# STM32G474 register map
File version: 2.9
CPU: CM4 r0p1, little endian, MPU, FPU, 4 interrupt priority bits
Registers are 32-bit, read-write, reset 0x0 unless marked. A register's access mark holds for its fields unless they carry their own. Offsets are from the block's base; [hi:lo] are bit positions; {n}, {i} and the like mark numbered series.

## PWR — Power control
Base 0x40007000
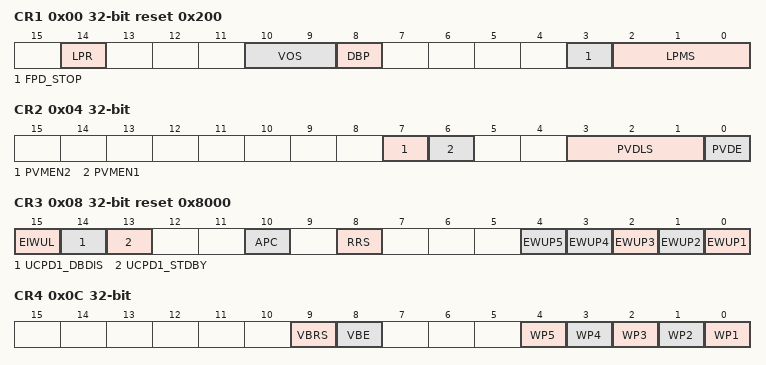
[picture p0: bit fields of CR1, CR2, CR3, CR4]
0x00 CR1 reset 0x200 — Power control register 1
  [14] LPR — Low-power run When this bit is set, the regulator is switched from main mode (MR) to low-power mode (LPR).
  [10:9] VOS — Voltage scaling range selection
  [8] DBP — Disable backup domain write protection In reset state, the RTC and backup registers are protected against parasitic write access. This bit must be set to enable write access to these registers.
  [3] FPD_STOP
  [2:0] LPMS — Low-power mode selection These bits select the low-power mode entered when CPU enters the deepsleep mode. 1xx: Shutdown mode Note: In Standby mode, SRAM2 can be preserved or not, depending on RRS bit configuration in PWR_CR3.
0x04 CR2 — Power control register 2
  [7] PVMEN2 — Peripheral voltage monitoring 4 enable: V<sub>DDA</sub> vs. DAC 1MSPS /DAC 15MSPS min voltage.
  [6] PVMEN1 — Peripheral voltage monitoring 3 enable: V<sub>DDA</sub> vs. ADC/COMP min voltage 1.62V
  [3:1] PVDLS — Programmable voltage detector level selection. These bits select the PVD falling threshold: Note: These bits are write-protected when the PVDL bit is set in the SYSCFG_CFGR2 register. The protection can be reset only by a system reset.
  [0] PVDE — Programmable voltage detector enable Note: This bit is write-protected when the PVDL bit is set in the SYSCFG_CFGR2 register. The protection can be reset only by a system reset.
0x08 CR3 reset 0x8000 — Power control register 3
  [15] EIWUL — Enable internal wakeup line
  [14] UCPD1_DBDIS — USB Type-C and Power Delivery Dead Battery disable. After exiting reset, the USB Type-C dead battery behavior is enabled, which may have a pull-down effect on CC1 and CC2 pins. It is recommended to disable it in all cases, either to stop this pull-down or to hand over control to the UCPD1 (which should therefore be initialized before doing the disable).
  [13] UCPD1_STDBY — UCPD1_STDBY USB Type-C and Power Delivery standby mode.
  [10] APC — Apply pull-up and pull-down configuration When this bit is set, the I/O pull-up and pull-down configurations defined in the PWR_PUCRx and PWR_PDCRx registers are applied. When this bit is cleared, the PWR_PUCRx and PWR_PDCRx registers are not applied to the I/Os.
  [8] RRS — SRAM2 retention in Standby mode
  [4] EWUP5 — Enable Wakeup pin WKUP5 When this bit is set, the external wakeup pin WKUP5 is enabled and triggers a wakeup from Standby or Shutdown event when a rising or a falling edge occurs.The active edge is configured via the WP5 bit in the PWR_CR4 register.
  [n-1] EWUP{n} (n=1..4) — Enable Wakeup pin WKUP{n} When this bit is set, the external wakeup pin WKUP{n} is enabled and triggers a wakeup from Standby or Shutdown event when a rising or a falling edge occurs. The active edge is configured via the WP{n} bit in the PWR_CR4 register.
0x0C CR4 — Power control register 4
  [9] VBRS — V<sub>BAT</sub> battery charging resistor selection
  [8] VBE — V<sub>BAT</sub> battery charging enable
  [n-1] WP{n} (n=1..5) — Wakeup pin WKUP{n} polarity This bit defines the polarity used for an event detection on external wake-up pin, WKUP{n}
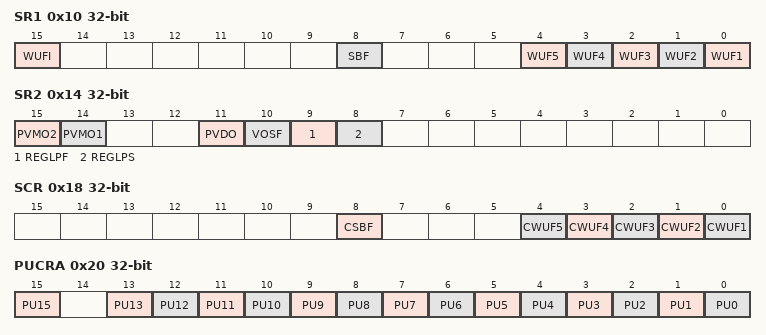
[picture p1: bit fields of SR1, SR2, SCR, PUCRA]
0x10 SR1 ro — Power status register 1
  [15] WUFI — Wakeup flag internal This bit is set when a wakeup is detected on the internal wakeup line. It is cleared when all internal wakeup sources are cleared.
  [8] SBF — Standby flag This bit is set by hardware when the device enters the Standby mode and is cleared by setting the CSBF bit in the PWR_SCR register, or by a power-on reset. It is not cleared by the system reset.
  [4] WUF5 — Wakeup flag 5 This bit is set when a wakeup event is detected on wakeup pin, WKUP5. It is cleared by writing 1 in the CWUF5 bit of the PWR_SCR register.
  [3] WUF4 — Wakeup flag 4 This bit is set when a wakeup event is detected on wakeup pin,WKUP4. It is cleared by writing 1 in the CWUF4 bit of the PWR_SCR register.
  [2] WUF3 — Wakeup flag 3 This bit is set when a wakeup event is detected on wakeup pin, WKUP3. It is cleared by writing 1 in the CWUF3 bit of the PWR_SCR register.
  [1] WUF2 — Wakeup flag 2 This bit is set when a wakeup event is detected on wakeup pin, WKUP2. It is cleared by writing 1 in the CWUF2 bit of the PWR_SCR register.
  [0] WUF1 — Wakeup flag 1 This bit is set when a wakeup event is detected on wakeup pin, WKUP1. It is cleared by writing 1 in the CWUF1 bit of the PWR_SCR register.
0x14 SR2 ro — Power status register 2
  [15] PVMO2 — Peripheral voltage monitoring output: V<sub>DDA</sub> vs. 1.8 V Note: PVMO2 is cleared when PVM2 is disabled (PVME = 0). After enabling PVM2, the PVM2 output is valid after the PVM2 wakeup time.
  [14] PVMO1 — Peripheral voltage monitoring output: V<sub>DDA</sub> vs. 1.62 V Note: PVMO1 is cleared when PVM1 is disabled (PVME = 0). After enabling PVM1, the PVM1 output is valid after the PVM1 wakeup time.
  [11] PVDO — Programmable voltage detector output
  [10] VOSF — Voltage scaling flag A delay is required for the internal regulator to be ready after the voltage scaling has been changed. VOSF indicates that the regulator reached the voltage level defined with VOS bits of the PWR_CR1 register.
  [9] REGLPF — Low-power regulator flag This bit is set by hardware when the MCU is in Low-power run mode. When the MCU exits the Low-power run mode, this bit remains at 1 until the regulator is ready in main mode. A polling on this bit must be done before increasing the product frequency. This bit is cleared by hardware when the regulator is ready.
  [8] REGLPS — Low-power regulator started This bit provides the information whether the low-power regulator is ready after a power-on reset or a Standby/Shutdown. If the Standby mode is entered while REGLPS bit is still cleared, the wakeup from Standby mode time may be increased.
0x18 SCR wo — Power status clear register
  [8] CSBF — Clear standby flag Setting this bit clears the SBF flag in the PWR_SR1 register.
  [n-1] CWUF{n} (n=1..5) — Clear wakeup flag {n} Setting this bit clears the WUF{n} flag in the PWR_SR1 register.
0x20 PUCRA — Power Port A pull-up control register
  [15] PU15 — Port A pull-up bit 15 When set, this bit activates the pull-up on PA[15] when APC bit is set in PWR_CR3 register. The pull-up is not activated if the corresponding PD15 bit is also set.
  [n] PU{n} (n=0..13) — Port A pull-up bit y (y=0..13) When set, this bit activates the pull-up on PA[y] when APC bit is set in PWR_CR3 register. The pull-up is not activated if the corresponding PDy bit is also set.
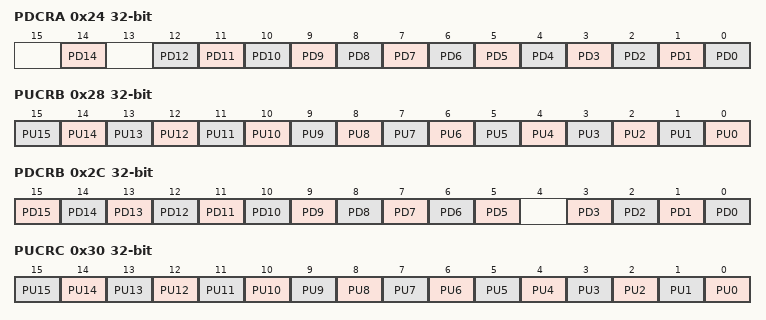
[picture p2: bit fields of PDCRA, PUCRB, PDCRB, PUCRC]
0x24 PDCRA — Power Port A pull-down control register
  [14] PD14 — Port A pull-down bit 14 When set, this bit activates the pull-down on PA[14] when APC bit is set in PWR_CR3 register.
  [n] PD{n} (n=0..12) — Port A pull-down bit y (y=0..12) When set, this bit activates the pull-down on PA[y] when APC bit is set in PWR_CR3 register.
0x28 PUCRB — Power Port B pull-up control register
  [n] PU{n} (n=0..15) — Port B pull-up bit y (y=0..15) When set, this bit activates the pull-up on PB[y] when APC bit is set in PWR_CR3 register. The pull-up is not activated if the corresponding PDy bit is also set.
0x2C PDCRB — Power Port B pull-down control register
  [n] PD{n} (n=5..15) — Port B pull-down bit y (y=5..15) When set, this bit activates the pull-down on PB[y] when APC bit is set in PWR_CR3 register.
  [n] PD{n} (n=0..3) — Port B pull-down bit y (y=0..3) When set, this bit activates the pull-down on PB[y] when APC bit is set in PWR_CR3 register.
0x30 PUCRC — Power Port C pull-up control register
  [n] PU{n} (n=0..15) — Port C pull-up bit y (y=0..15) When set, this bit activates the pull-up on PC[y] when APC bit is set in PWR_CR3 register. The pull-up is not activated if the corresponding PDy bit is also set.
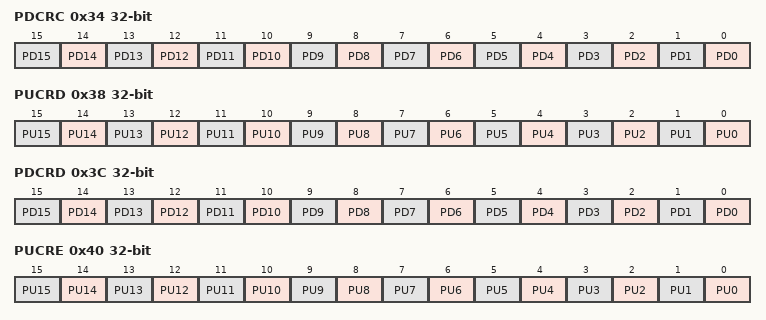
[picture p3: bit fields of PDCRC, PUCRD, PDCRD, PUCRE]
0x34 PDCRC — Power Port C pull-down control register
  [n] PD{n} (n=0..15) — Port C pull-down bit y (y=0..15) When set, this bit activates the pull-down on PC[y] when APC bit is set in PWR_CR3 register.
0x38 PUCRD — Power Port D pull-up control register
  [n] PU{n} (n=0..15) — Port D pull-up bit y (y=0..15) When set, this bit activates the pull-up on PD[y] when APC bit is set in PWR_CR3 register. The pull-up is not activated if the corresponding PDy bit is also set.
0x3C PDCRD — Power Port D pull-down control register
  [n] PD{n} (n=0..15) — Port D pull-down bit y (y=0..15) When set, this bit activates the pull-down on PD[y] when APC bit is set in PWR_CR3 register.
0x40 PUCRE — Power Port E pull-up control register
  [n] PU{n} (n=0..15) — Port E pull-up bit y (y=0..15) When set, this bit activates the pull-up on PE[y] when APC bit is set in PWR_CR3 register. The pull-up is not activated if the corresponding PDy bit is also set.
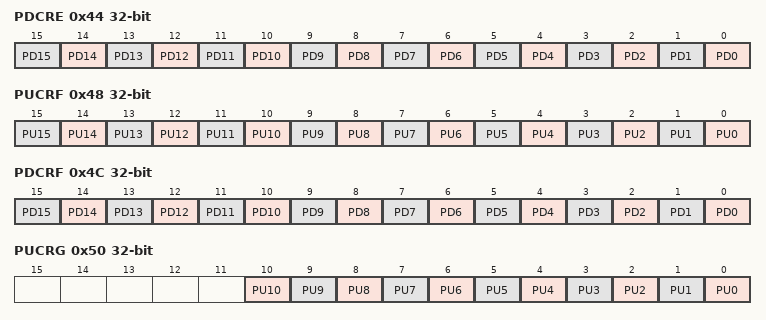
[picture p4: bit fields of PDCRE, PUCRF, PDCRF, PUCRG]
0x44 PDCRE — Power Port E pull-down control register
  [n] PD{n} (n=0..15) — Port E pull-down bit y (y=0..15) When set, this bit activates the pull-down on PE[y] when APC bit is set in PWR_CR3 register.
0x48 PUCRF — Power Port F pull-up control register
  [n] PU{n} (n=0..15) — Port F pull-up bit y (y=0..15) When set, this bit activates the pull-up on PF[y] when APC bit is set in PWR_CR3 register. The pull-up is not activated if the corresponding PDy bit is also set.
0x4C PDCRF — Power Port F pull-down control register
  [n] PD{n} (n=0..15) — Port F pull-down bit y (y=0..15) When set, this bit activates the pull-down on PF[y] when APC bit is set in PWR_CR3 register.
0x50 PUCRG — Power Port G pull-up control register
  [n] PU{n} (n=0..10) — Port G pull-up bit y (y=0..10) When set, this bit activates the pull-up on PG[y] when APC bit is set in PWR_CR3 register. The pull-up is not activated if the corresponding PDy bit is also set.
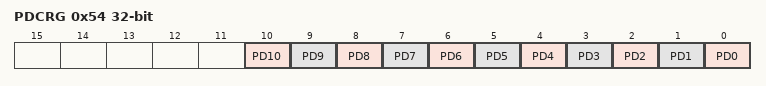
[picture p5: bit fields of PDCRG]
0x54 PDCRG — Power Port G pull-down control register
  [n] PD{n} (n=0..10) — Port G pull-down bit y (y=0..10) When set, this bit activates the pull-down on PG[y] when APC bit is set in PWR_CR3 register.
0x80 CR5 reset 0x100 — Power control register
  [8] R1MODE — Main regular range 1 mode This bit is only valid for the main regulator in range 1 and has no effect on range 2. It is recommended to reset this bit when the system frequency is greater than 150 MHz. Refer to
